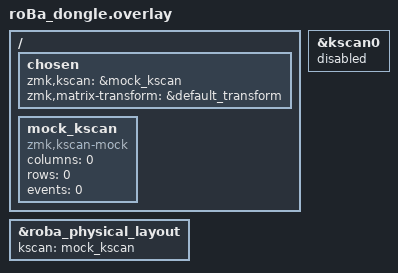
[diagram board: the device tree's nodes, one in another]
#include <dt-bindings/zmk/matrix_transform.h>
#include "roBa.dtsi"

/ {
    chosen {
        zmk,kscan = &mock_kscan;
        zmk,matrix-transform = &default_transform;
    };

    mock_kscan: mock_kscan {
        compatible = "zmk,kscan-mock";
        columns = <0>;
        rows = <0>;
        events = <0>;
    };
};

/* 物理レイアウトのキースキャン参照先をダミーノードへ上書き */
&roba_physical_layout {
    kscan = <&mock_kscan>;
};

/* roBa.dtsi で定義されている元の物理マトリクスを無効化 */
&kscan0 {
    status = "disabled";
};
